# 3065HRPICZ register map
File version: 1.0
Registers are 32-bit, access per field, reset 0x0 unless marked. A register's access mark holds for its fields unless they carry their own. Offsets are from the block's base; lines under a group give offsets from that group; [hi:lo] are bit positions; {n}, {i} and the like mark numbered series; 'fields as' and 'values as' point back to an identical list; <NAME> marks a mode.

## Memory map
0x10000000 CRG size 0x204 — CRG_PERIAPBIF peripheral interface
0x10010000 CMM size 0x2C — CMM_APB_REG peripheral interface
0x10020000 CFD size 0x20 — CFD_APB_REG peripheral interface
0x10100000 SYSCTRL0 size 0x8000 — SYSCTRL0_REG peripheral interface
0x10100000 SYSCTRL1 size 0xFFFC — SYSCTRL1_REG peripheral interface
0x14000000 UART0 size 0x400 — UART
0x14001000 UART1 size 0x400
0x14002000 UART2 size 0x400
0x14100000 I2C size 0xEC — I2C peripheral interface
0x14200000 SPI size 0x400 — Serial peripheral interface
0x14300000 TIMER0 size 0x20 — TIMER peripheral interface
0x14300020 TIMER1 size 0x20
0x14301000 TIMER2 size 0x20
0x14400000 WDG size 0x1000
0x14401000 IWDG size 0x1000
0x14500000 GPIO0 size 0x1000 — GPIO
0x14501000 GPIO1 size 0x1000
0x14502000 GPIO2 size 0x1000
0x14503000 GPIO3 size 0x1000
0x14504000 GPIO4 size 0x1000
0x14505000 GPIO5 size 0x1000
0x14506000 GPIO6 size 0x1000
0x14507000 GPIO7 size 0x1000
0x14600000 CAN size 0x1000
0x14700000 GPT0 size 0x1000
0x14701000 GPT1 size 0x1000
0x14710000 FLASH size 0x608 — HIEFC_COMMON_REGS peripheral interface
0x14710800 FLASH_EX size 0x634 — HIEFC_T40SST_REGS peripheral interface
0x147E0000 IOCMG_AON size 0x10 — IOCMG_AON peripheral interface
0x147E0000 PMC size 0xF10 — PMC_REG peripheral interface
0x147F0000 IOCMG_CORE size 0x30 — IOCMG_CORE peripheral interface
0x14800000 CRC size 0x29 — CRC_CFG peripheral interface
0x149F0000 IOCMG_ANA size 0xC4 — IOCMG_ANA peripheral interface
0x14A00000 APT0 size 0x734 — APT_REG peripheral interface
0x14A01000 APT1 size 0x734
0x14A02000 APT2 size 0x734
0x14A06000 APT6 size 0x734
0x14A07000 APT7 size 0x734
0x14A08000 APT8 size 0x734
0x14B00000 CAPM0 size 0x50 — capm_ccr peripheral interface
0x14B01000 CAPM1 size 0x50
0x14B02000 CAPM2 size 0x50
0x14B03000 CAPM_COMM size 0x34 — capm_comm peripheral interface
0x18000000 ADC0 size 0x1D8 — ADC peripheral interface
0x18001000 ADC1 size 0x1D8
0x18002000 ADC2 size 0x1D8
0x18200000 PGA0 size 0x10 — PGA_CFG peripheral interface
0x18201000 PGA1 size 0x10
0x18202000 PGA2 size 0x10
0x18300000 ACMP0 size 0x1C — ACMP peripheral interface
0x18300000 DAC0 size 0x8 — 数模转换器
0x18301000 ACMP1 size 0x1C
0x18301000 DAC1 size 0x8
0x18302000 ACMP2 size 0x1C
0x18302000 DAC2 size 0x8
0x1C000000 DMA size 0x20 — DMA peripheral interface

## Interrupts
4 IOCMG_AON
4 PGA_CFG (PGA0)
5 ACMP (ACMP0)
8 CFD_APB_REG (CFD)
8 DMA
8 TIMER (TIMER0)
8 capm_comm (CAPM_COMM)
11 CMM_APB_REG (CMM)
11 CRC_CFG (CRC)
12 IOCMG_CORE
19 capm_ccr (CAPM0)
20 SYSCTRL1_REG (SYSCTRL1)
21 PMC_REG (PMC)
26 SYSCTRL0_REG (SYSCTRL0)
27 HIEFC_COMMON_REGS (FLASH)
35 HIEFC_T40SST_REGS (FLASH_EX)
35 SPI0 (SPI)
43 CRG_PERIAPBIF (CRG)
49 IOCMG_ANA
57 I2C
63 ADC (ADC0)
63 DAC (DAC0)
65 APT_REG (APT0)
71 CAN
71 GPIO (GPIO0)
71 GPT (GPT0)
71 UART (UART0)
71 WDG

## ACMP0 — ACMP peripheral interface
Base 0x18300000
Same registers: ACMP1 0x18301000, ACMP2 0x18302000
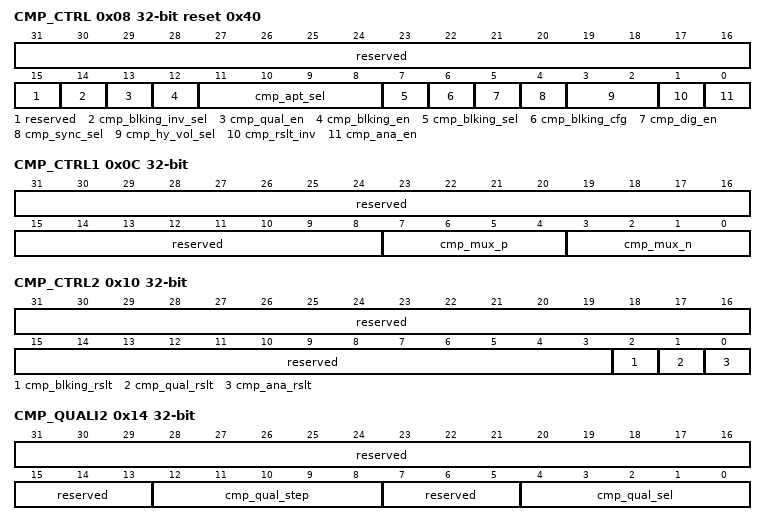
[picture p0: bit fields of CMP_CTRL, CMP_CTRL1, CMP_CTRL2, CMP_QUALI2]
0x08 CMP_CTRL reset 0x40 — CMP控制。
  [31:15] reserved ro — 保留。
  [14] cmp_blking_inv_sel rw — CMP消隐生效的电平选择。 0：消隐信号为0时，表示消隐生效； 1：消隐信号为1时，表示消隐生效。
  [13] cmp_qual_en rw — CMP的比较结果选择，和cmp_sync_sel共同决定比较结果来源 [cmp_sync_sel,cmp_qual_en]： 00:模拟输出的原始比较结果直接送至输出端口； 01:经过去抖后的比较结果送至输出端口； 10:经过单拍同步后的比较结果送至端口； 11:保留。
  [12] cmp_blking_en rw — 消隐信号使能： 0：不使用消隐； 1：使用消隐。
  [11:8] cmp_apt_sel rw — 选择来自APT屏蔽窗口的APT标号。 0x0：blanking0； 0x1：blanking1； 0x2：blanking2； 0x3：blanking3； 0x4：blanking4； 0x5：blanking5； 0x6：blanking6； 0x7：blanking7； 0x8：blanking8； 其他：无效，默认为0。
  [7] cmp_blking_sel rw — 消隐信号来源。 0：APT 屏蔽窗口； 1：软件控制。
  [6] cmp_blking_cfg rw — 软件的消隐信号，消隐极性受cmp_blking_inv_sel控制。
  [5] cmp_dig_en rw — CMP数字部分使能。 0：不使能； 1：使能。
  [4] cmp_sync_sel rw — CMP的比较结果选择，和cmp_qual_en共同决定比较结果来源。
  [3:2] cmp_hy_vol_sel rw — 选择比较器迟滞电压。 00：无迟滞； 01：10mV迟滞； 10：20mV迟滞； 11：30mV迟滞。
  [1] cmp_rslt_inv rw — 比较结果输出极性选择。 0：VINP大于VINN，CMP_OUT=1； 1：VINP大于VINN，CMP_OUT=0。
  [0] cmp_ana_en rw — CMP电源使能。 0：不使能； 1：使能。
0x0C CMP_CTRL1 — CMP控制。
  [31:8] reserved ro — 保留。
  [7:4] cmp_mux_p rw — VINP选择，只能有1bit为1。 0x1：VINP[0]； 0x2：VINP[1]； 0x4：VINP[2]； 0x8：VINP[3]； 其他：保留。
  [3:0] cmp_mux_n rw — VINN选择，只能有1bit为1。 0x1：VINN[0]； 0x2：VINN[1]； 0x4：VINN[2]； 0x8：VINN[3]； 其他：保留。
0x10 CMP_CTRL2 ro — CMP控制。
  [31:3] reserved — 保留。
  [2] cmp_blking_rslt — 消隐后的比较结果。
  [1] cmp_qual_rslt — 去抖后的比较结果。
  [0] cmp_ana_rslt — 模拟原始的比较结果。
0x14 CMP_QUALI2 — CMP去抖。
  [31:13] reserved ro — 保留。
  [12:8] cmp_qual_step rw — 去抖步进，每几个时钟采集一次结果，配置为0则每个时钟都采集结果。
  [7:5] reserved ro — 保留。
  [4:0] cmp_qual_sel rw — 去抖档位，连续多少比较结果相同才跳转结果，配置为0和1均表示单次结果输出。
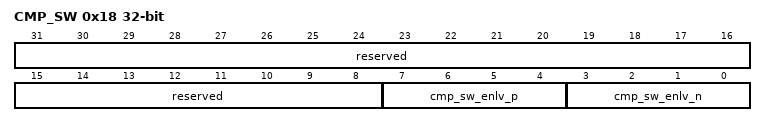
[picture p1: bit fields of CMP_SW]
0x18 CMP_SW — CMP输入SW控制。
  [31:8] reserved ro — 保留。
  [7:4] cmp_sw_enlv_p rw — ACMP P端外部SW控制，与通道选择联合配置，仅在输入为IO时需要配置。 0x1：VINP[0]； 0x2：VINP[1]； 0x4：VINP[2]； 0x8：VINP[3]； 其他：保留。
  [3:0] cmp_sw_enlv_n rw — ACMP N端外部SW控制，与通道选择联合配置，仅在输入为IO时需要配置。 0x1：VINN[0]； 0x2：VINN[1]； 0x4：VINN[2]； 0x8：VINN[3]； 其他：保留。
